# HDSC_HC32F072 register map
Vendor: HDSC Co.Ltd; Series: ARMCM0P; File version: 1.2
CPU: CM0 r0p0, little endian, no MPU, no FPU, 3 interrupt priority bits
Registers are 32-bit, read-write, reset 0x0 unless marked. A register's access mark holds for its fields unless they carry their own. Offsets are from the block's base; [hi:lo] are bit positions; {n}, {i} and the like mark numbered series.

## LVD
Base 0x40002400; alternate view of ADC
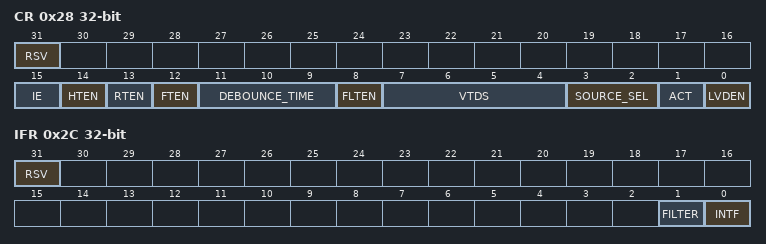
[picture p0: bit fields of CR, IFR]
0x28 CR (reset mask 0xFFFF)
  [31] RSV, [15] IE, [14] HTEN, [13] RTEN, [12] FTEN, [11:9] DEBOUNCE_TIME, [8] FLTEN, [7:4] VTDS, [3:2] SOURCE_SEL, [1] ACT, [0] LVDEN
0x2C IFR (reset mask 0x3)
  [31] RSV, [1] FILTER, [0] INTF

## OPA
Base 0x40002400; alternate view of ADC
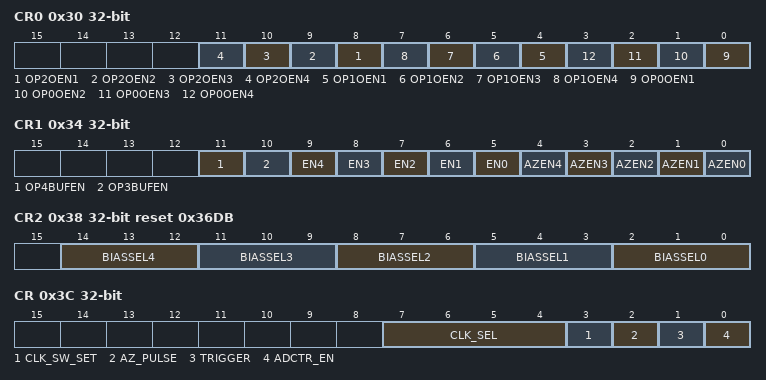
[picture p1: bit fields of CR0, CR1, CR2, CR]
0x30 CR0
  [n+7] OP2OEN{n} (n=1..4), [n+3] OP1OEN{n} (n=1..4), [n-1] OP0OEN{n} (n=1..4)
0x34 CR1
  [11] OP4BUFEN, [10] OP3BUFEN, [n+5] EN{n} (n=0..4), [n] AZEN{n} (n=0..4)
0x38 CR2 reset 0x36DB
  [3n+2:3n] BIASSEL{n} (n=0..4)
0x3C CR
  [7:4] CLK_SEL, [3] CLK_SW_SET, [2] AZ_PULSE, [1] TRIGGER, [0] ADCTR_EN

## PCA
Base 0x40001000
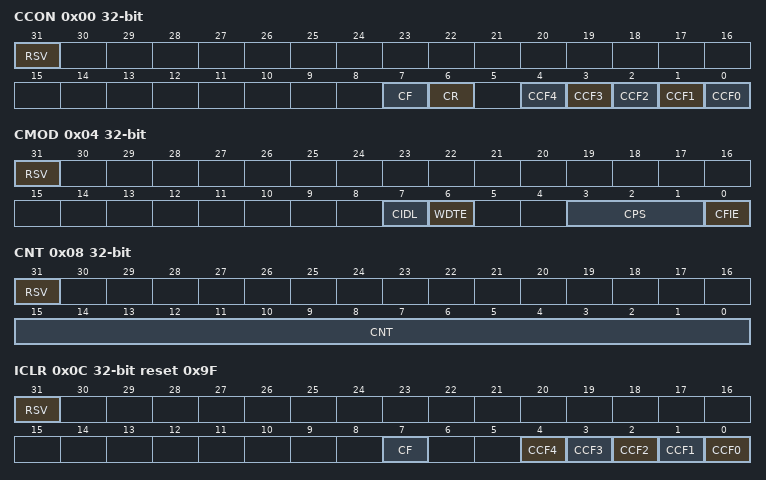
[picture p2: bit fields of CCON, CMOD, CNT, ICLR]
0x00 CCON (reset mask 0xDF)
  [31] RSV, [7] CF, [6] CR, [n] CCF{n} (n=0..4)
0x04 CMOD (reset mask 0xCF)
  [31] RSV, [7] CIDL, [6] WDTE, [3:1] CPS, [0] CFIE
0x08 CNT (reset mask 0xFFFF)
  [31] RSV, [15:0] CNT
0x0C ICLR wo reset 0x9F (reset mask 0x9F)
  [31] RSV rw, [7] CF, [n] CCF{n} (n=0..4)
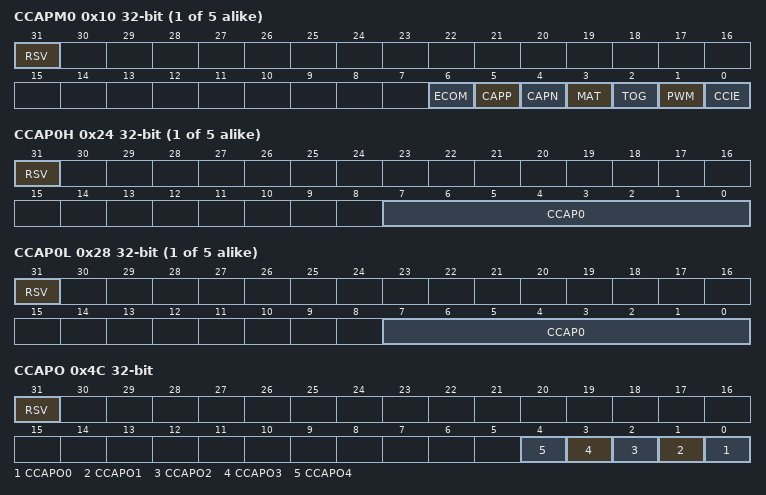
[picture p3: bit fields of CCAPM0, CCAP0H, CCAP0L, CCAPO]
{0x10+4i} CCAPM{i} (reset mask 0x7F) (i=0..4)
  [31] RSV, [6] ECOM, [5] CAPP, [4] CAPN, [3] MAT, [2] TOG, [1] PWM, [0] CCIE
{0x24+8i} CCAP{i}H (reset mask 0xFF) (i=0..4)
  [31] RSV, [7:0] CCAP{i}
{0x28+8i} CCAP{i}L (reset mask 0xFF) (i=0..4)
  [31] RSV, [7:0] CCAP{i}
0x4C CCAPO (reset mask 0x1F)
  [31] RSV, [n] CCAPO{n} (n=0..4)
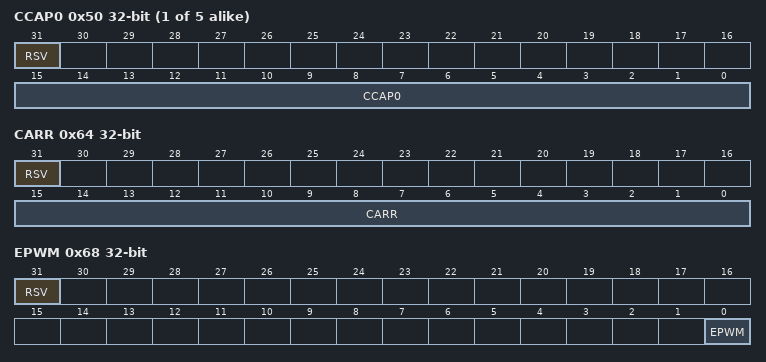
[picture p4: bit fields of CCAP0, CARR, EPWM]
{0x50+4i} CCAP{i} (reset mask 0xFFFF) (i=0..4)
  [31] RSV, [15:0] CCAP{i}
0x64 CARR (reset mask 0xFFFF)
  [31] RSV, [15:0] CARR
0x68 EPWM (reset mask 0x1)
  [31] RSV, [0] EPWM

## RAM
Base 0x40020400
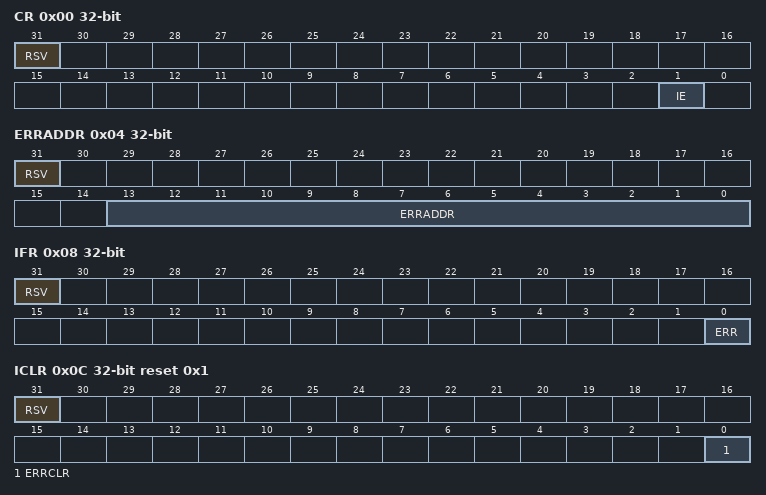
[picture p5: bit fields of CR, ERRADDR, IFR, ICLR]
0x00 CR (reset mask 0x3)
  [31] RSV, [1] IE
0x04 ERRADDR ro (reset mask 0x1FFF)
  [31] RSV rw, [13:0] ERRADDR
0x08 IFR ro (reset mask 0x1)
  [31] RSV, [0] ERR
0x0C ICLR wo reset 0x1 (reset mask 0x1)
  [31] RSV ro, [0] ERRCLR

## RESET
Base 0x4000201C
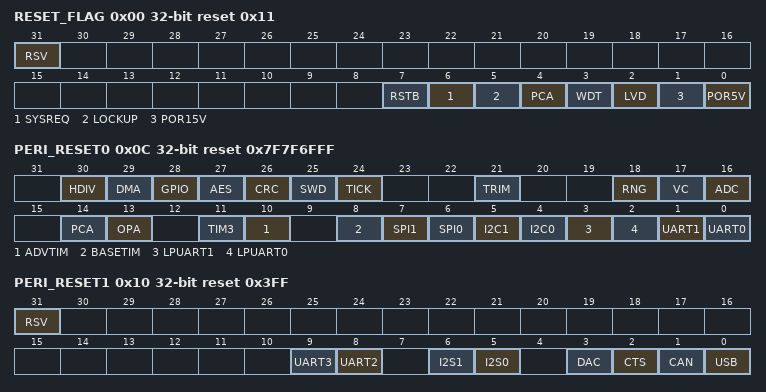
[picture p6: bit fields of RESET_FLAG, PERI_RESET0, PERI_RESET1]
0x00 RESET_FLAG reset 0x11 (reset mask 0xFF)
  [31] RSV, [7] RSTB, [6] SYSREQ, [5] LOCKUP, [4] PCA, [3] WDT, [2] LVD, [1] POR15V, [0] POR5V
0x0C PERI_RESET0 reset 0x7F7F6FFF
  [30] HDIV, [29] DMA, [28] GPIO, [27] AES, [26] CRC, [25] SWD, [24] TICK, [21] TRIM, [18] RNG, [17] VC, [16] ADC, [14] PCA, [13] OPA, [11] TIM3, [10] ADVTIM, [8] BASETIM, [7] SPI1, [6] SPI0, [5] I2C1, [4] I2C0, [3] LPUART1, [2] LPUART0, [1] UART1, [0] UART0
0x10 PERI_RESET1 reset 0x3FF (reset mask 0x3FFF)
  [31] RSV, [9] UART3, [8] UART2, [6] I2S1, [5] I2S0, [3] DAC, [2] CTS, [1] CAN, [0] USB

## SPI0 — desc SPI
Base 0x40000800
Same registers: SPI1 0x40004800
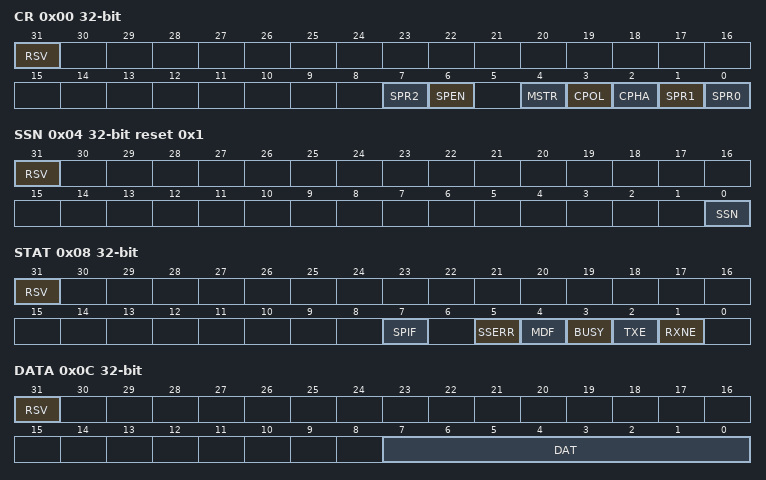
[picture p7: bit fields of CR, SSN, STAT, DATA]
0x00 CR (reset mask 0xDF)
  [31] RSV, [7] SPR2, [6] SPEN, [4] MSTR, [3] CPOL, [2] CPHA, [1] SPR1, [0] SPR0
0x04 SSN reset 0x1 (reset mask 0x1)
  [31] RSV, [0] SSN
0x08 STAT ro (reset mask 0xBE)
  [31] RSV rw, [7] SPIF, [5] SSERR, [4] MDF, [3] BUSY, [2] TXE, [1] RXNE
0x0C DATA (reset mask 0xFF)
  [31] RSV, [7:0] DAT
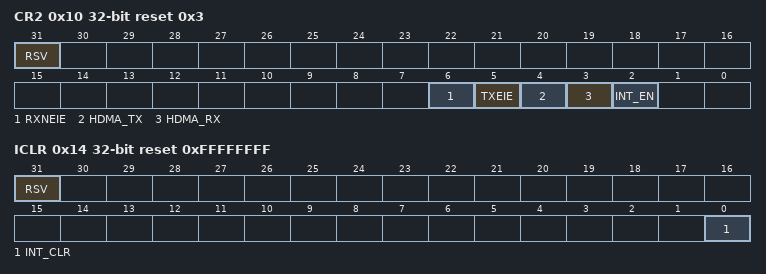
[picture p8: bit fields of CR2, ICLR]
0x10 CR2 reset 0x3 (reset mask 0x7C)
  [31] RSV, [6] RXNEIE, [5] TXEIE, [4] HDMA_TX, [3] HDMA_RX, [2] INT_EN
0x14 ICLR wo reset 0xFFFFFFFF (reset mask 0x1)
  [31] RSV rw, [0] INT_CLR

## SYSCTRL
Base 0x40002000
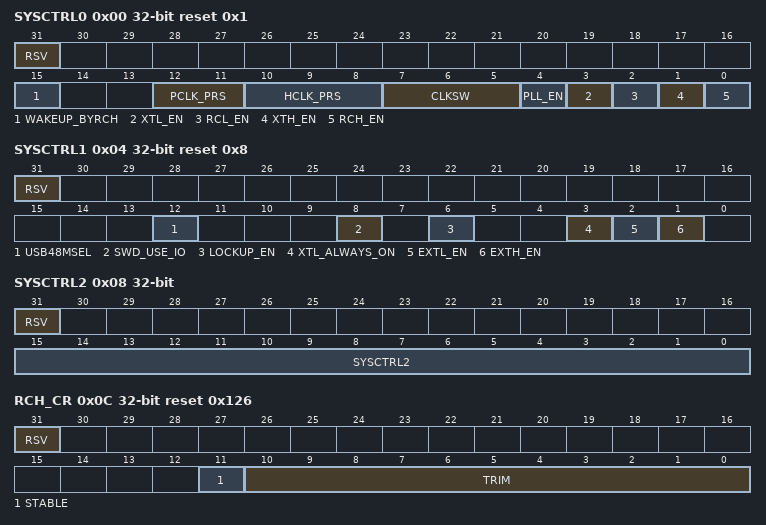
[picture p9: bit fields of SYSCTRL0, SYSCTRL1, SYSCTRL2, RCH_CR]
0x00 SYSCTRL0 reset 0x1 (reset mask 0x9FFF)
  [31] RSV, [15] WAKEUP_BYRCH, [12:11] PCLK_PRS, [10:8] HCLK_PRS, [7:5] CLKSW, [4] PLL_EN, [3] XTL_EN, [2] RCL_EN, [1] XTH_EN, [0] RCH_EN
0x04 SYSCTRL1 reset 0x8 (reset mask 0xF7E)
  [31] RSV, [12] USB48MSEL, [8] SWD_USE_IO, [6] LOCKUP_EN, [3] XTL_ALWAYS_ON, [2] EXTL_EN, [1] EXTH_EN
0x08 SYSCTRL2 wo (reset mask 0xFFFF)
  [31] RSV rw, [15:0] SYSCTRL2
0x0C RCH_CR reset 0x126 (reset mask 0xFFF)
  [31] RSV, [11] STABLE ro, [10:0] TRIM
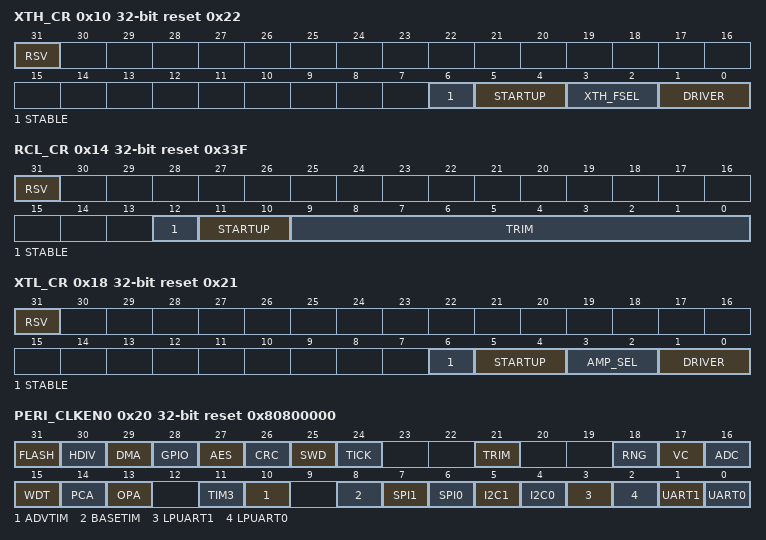
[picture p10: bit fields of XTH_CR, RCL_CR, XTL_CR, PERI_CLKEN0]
0x10 XTH_CR reset 0x22 (reset mask 0x7F)
  [31] RSV, [6] STABLE ro, [5:4] STARTUP, [3:2] XTH_FSEL, [1:0] DRIVER
0x14 RCL_CR reset 0x33F (reset mask 0x1FFF)
  [31] RSV, [12] STABLE ro, [11:10] STARTUP, [9:0] TRIM
0x18 XTL_CR reset 0x21 (reset mask 0x7F)
  [31] RSV, [6] STABLE ro, [5:4] STARTUP, [3:2] AMP_SEL, [1:0] DRIVER
0x20 PERI_CLKEN0 reset 0x80800000
  [31] FLASH, [30] HDIV, [29] DMA, [28] GPIO, [27] AES, [26] CRC, [25] SWD, [24] TICK, [21] TRIM, [18] RNG, [17] VC, [16] ADC, [15] WDT, [14] PCA, [13] OPA, [11] TIM3, [10] ADVTIM, [8] BASETIM, [7] SPI1, [6] SPI0, [5] I2C1, [4] I2C0, [3] LPUART1, [2] LPUART0, [1] UART1, [0] UART0
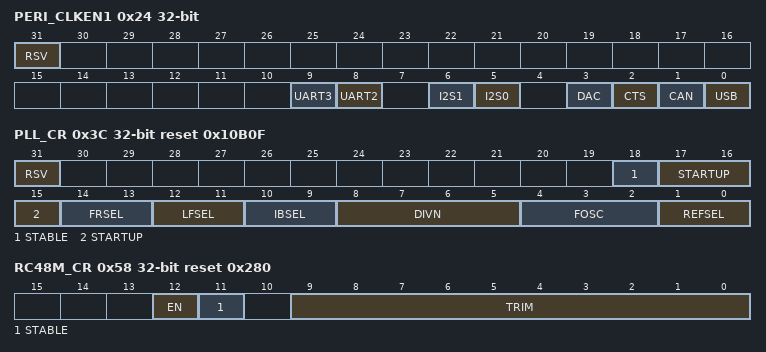
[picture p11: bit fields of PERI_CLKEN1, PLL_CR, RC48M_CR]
0x24 PERI_CLKEN1 (reset mask 0xFFF)
  [31] RSV, [9] UART3, [8] UART2, [6] I2S1, [5] I2S0, [3] DAC, [2] CTS, [1] CAN, [0] USB
0x3C PLL_CR reset 0x10B0F (reset mask 0x3FFFF)
  [31] RSV, [18] STABLE, [17:15] STARTUP, [14:13] FRSEL, [12:11] LFSEL, [10:9] IBSEL, [8:5] DIVN, [4:2] FOSC, [1:0] REFSEL
0x54 OVCK_CR
  [0] OVCK
0x58 RC48M_CR reset 0x280 (reset mask 0xFF)
  [12] EN, [11] STABLE ro, [9:0] TRIM
